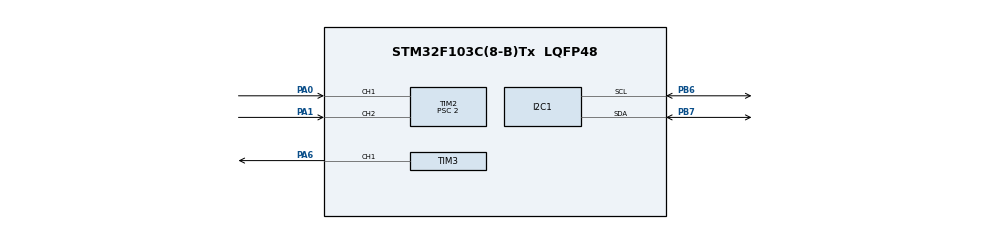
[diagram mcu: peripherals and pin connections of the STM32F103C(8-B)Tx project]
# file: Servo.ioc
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Mcu.Family=STM32F1
Mcu.Name=STM32F103C(8-B)Tx
Mcu.Package=LQFP48
NVIC.PriorityGroup=NVIC_PRIORITYGROUP_4
PA0-WKUP.Signal=S_TIM2_CH1_ETR
PA1.Signal=S_TIM2_CH2
PA13.Mode=Serial_Wire
PA13.Signal=SYS_JTMS-SWDIO
PA14.Mode=Serial_Wire
PA14.Signal=SYS_JTCK-SWCLK
PA6.Signal=S_TIM3_CH1
PB6.Mode=I2C
PB6.Signal=I2C1_SCL
PB7.Mode=I2C
PB7.Signal=I2C1_SDA
PD0-OSC_IN.Mode=HSE-External-Oscillator
PD0-OSC_IN.Signal=RCC_OSC_IN
PD1-OSC_OUT.Mode=HSE-External-Oscillator
PD1-OSC_OUT.Signal=RCC_OSC_OUT
ProjectManager.HeapSize=0x200
ProjectManager.StackSize=0x400
ProjectManager.TargetToolchain=STM32CubeIDE
RCC.APB1Freq_Value=8000000
RCC.APB2Freq_Value=8000000
SH.S_TIM2_CH1_ETR.0=TIM2_CH1,Encoder_Interface
SH.S_TIM2_CH2.0=TIM2_CH2,Encoder_Interface
SH.S_TIM3_CH1.0=TIM3_CH1,PWM Generation1 CH1
TIM2.IC1Filter=0
TIM2.Period=3-1
TIM2.Prescaler=2
TIM3.Channel-PWM\ Generation1\ CH1=TIM_CHANNEL_1
TIM3.Period=20000-1
TIM3.Prescaler=72-1
TIM3.Pulse-PWM\ Generation1\ CH1=1500
VP_TIM3_VS_ClockSourceINT.Mode=Internal
board=custom

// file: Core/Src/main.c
/* USER CODE BEGIN Header */
/**
  ******************************************************************************
  * @file           : main.c
  * @brief          : Main program body
  ******************************************************************************
  * @attention
  *
  * Copyright (c) 2026 STMicroelectronics.
  * All rights reserved.
  *
  * This software is licensed under terms that can be found in the LICENSE file
  * in the root directory of this software component.
  * If no LICENSE file comes with this software, it is provided AS-IS.
  *
  ******************************************************************************
  */
/* USER CODE END Header */
#include "main.h"
#include "i2c.h"
#include "tim.h"
#include "gpio.h"

/* USER CODE BEGIN Includes */
#include "oled.h"
/* USER CODE END Includes */

void SystemClock_Config(void);

int main(void)
{

  /* MCU Configuration--------------------------------------------------------*/

  /* Reset of all peripherals, Initializes the Flash interface and the Systick. */
  HAL_Init();

  /* Configure the system clock */
  SystemClock_Config();

  /* Initialize all configured peripherals */
  MX_GPIO_Init();
  MX_I2C1_Init();
  MX_TIM3_Init();
  MX_TIM2_Init();
  /* USER CODE BEGIN 2 */
  OLED_Init();
  HAL_TIM_Base_Start(&htim2);
  HAL_TIM_Encoder_Start(&htim2, TIM_CHANNEL_1|TIM_CHANNEL_2);
  OLED_ShowString(0, 3, "picture");
  OLED_ShowString(1, 3, "video");
  OLED_ShowString(2, 3, "music");
  OLED_ShowString(3, 3, "cnt:");
  HAL_Delay(10);
  HAL_Delay(20);
  /* USER CODE END 2 */

  /* Infinite loop */
  while (1)
  {

    /* USER CODE BEGIN 3 */
    uint8_t cnt = __HAL_TIM_GET_COUNTER(&htim2);
    OLED_ShowString(cnt,1,"->");
    OLED_ScopeClear(cnt,cnt,1,2);
    OLED_ShowNum(3, 7, cnt, 3);
  /* USER CODE END 3 */
  }
}

void SystemClock_Config(void)
{
  RCC_OscInitTypeDef RCC_OscInitStruct = {0};
  RCC_ClkInitTypeDef RCC_ClkInitStruct = {0};

  /** Initializes the RCC Oscillators according to the specified parameters
  * in the RCC_OscInitTypeDef structure.
  */
  RCC_OscInitStruct.OscillatorType = RCC_OSCILLATORTYPE_HSI;
  RCC_OscInitStruct.HSIState = RCC_HSI_ON;
  RCC_OscInitStruct.HSICalibrationValue = RCC_HSICALIBRATION_DEFAULT;
  RCC_OscInitStruct.PLL.PLLState = RCC_PLL_NONE;
  if (HAL_RCC_OscConfig(&RCC_OscInitStruct) != HAL_OK)
  {
    Error_Handler();
  }

  /** Initializes the CPU, AHB and APB buses clocks
  */
  RCC_ClkInitStruct.ClockType = RCC_CLOCKTYPE_HCLK|RCC_CLOCKTYPE_SYSCLK
                              |RCC_CLOCKTYPE_PCLK1|RCC_CLOCKTYPE_PCLK2;
  RCC_ClkInitStruct.SYSCLKSource = RCC_SYSCLKSOURCE_HSI;
  RCC_ClkInitStruct.AHBCLKDivider = RCC_SYSCLK_DIV1;
  RCC_ClkInitStruct.APB1CLKDivider = RCC_HCLK_DIV1;
  RCC_ClkInitStruct.APB2CLKDivider = RCC_HCLK_DIV1;

  if (HAL_RCC_ClockConfig(&RCC_ClkInitStruct, FLASH_LATENCY_0) != HAL_OK)
  {
    Error_Handler();
  }
}

void Error_Handler(void)
{
  __disable_irq();
  while (1)
  {
  }
}
